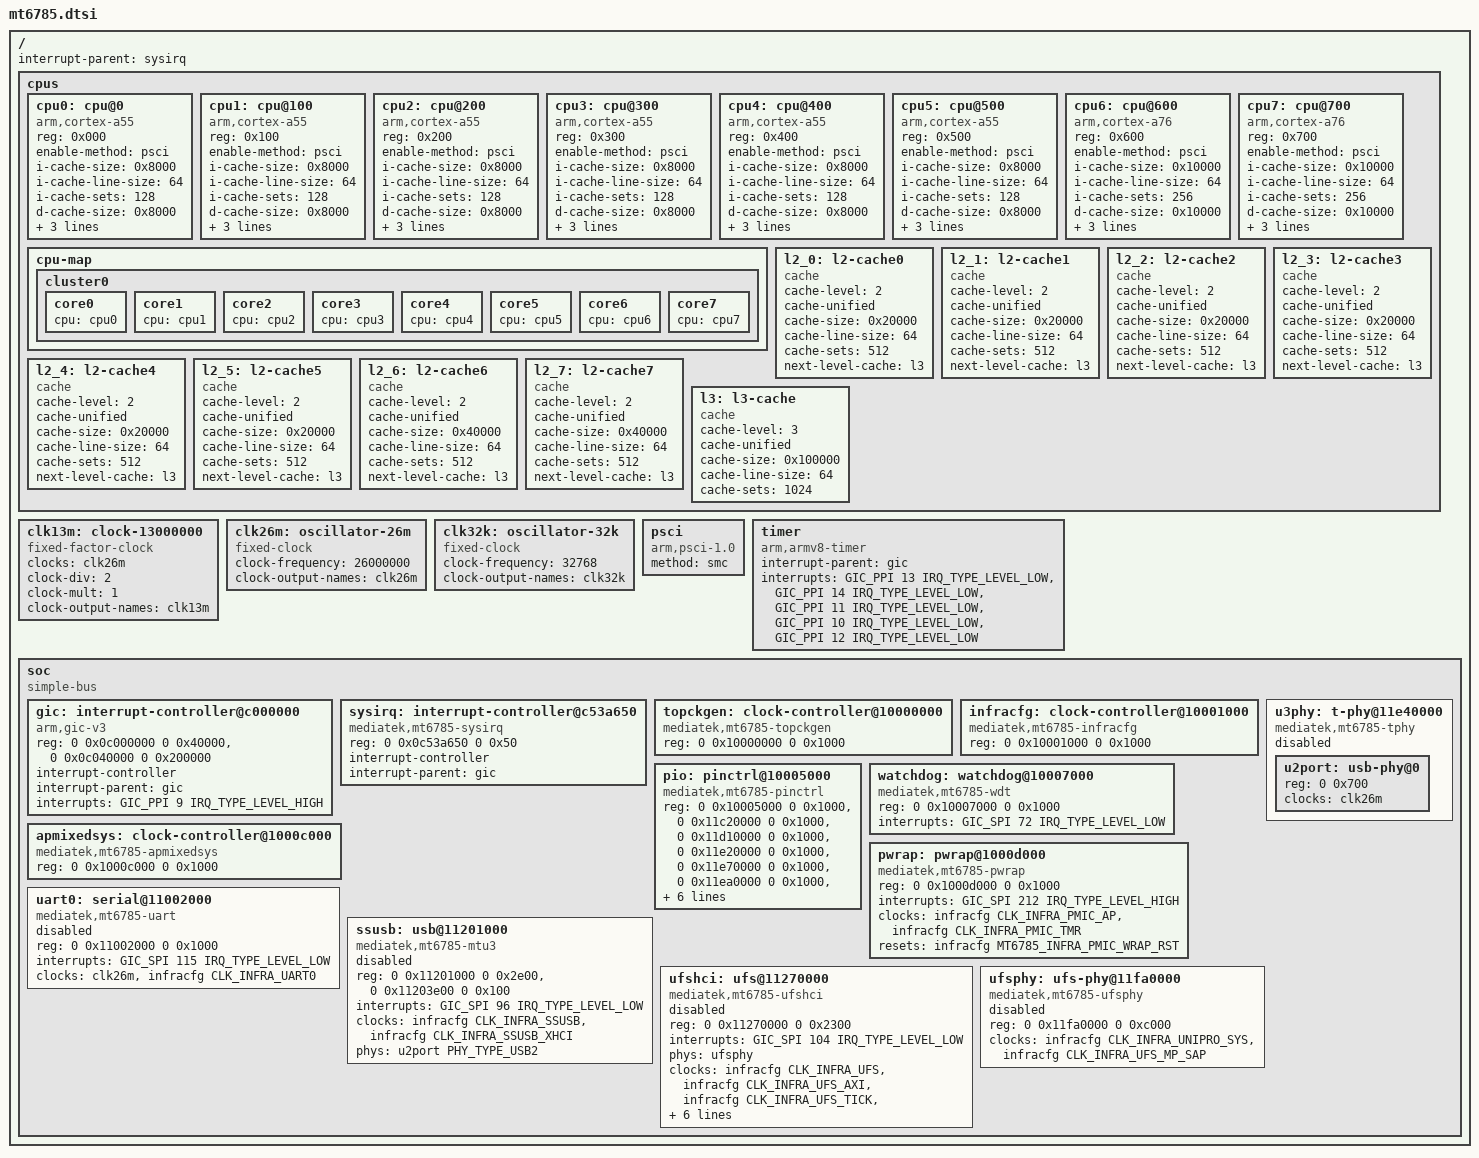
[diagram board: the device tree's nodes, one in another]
// SPDX-License-Identifier: (GPL-2.0 OR MIT)
/* Copyright (c) 2025 Dinolek <git@dinolek.me> */

#include <dt-bindings/clock/mediatek,mt6785-clk.h>
#include <dt-bindings/interrupt-controller/arm-gic.h>
#include <dt-bindings/interrupt-controller/irq.h>
#include <dt-bindings/phy/phy.h>
#include <dt-bindings/reset/mediatek,mt6785-resets.h>

/ {
	#address-cells = <2>;
	#size-cells = <2>;
	interrupt-parent = <&sysirq>;

	cpus {
		#address-cells = <1>;
		#size-cells = <0>;

		cpu0: cpu@0 {
			device_type = "cpu";
			compatible = "arm,cortex-a55";
			reg = <0x000>;
			enable-method = "psci";
			i-cache-size = <0x8000>;
			i-cache-line-size = <64>;
			i-cache-sets = <128>;
			d-cache-size = <0x8000>;
			d-cache-line-size = <64>;
			d-cache-sets = <128>;
			next-level-cache = <&l2_0>;
		};

		cpu1: cpu@100 {
			device_type = "cpu";
			compatible = "arm,cortex-a55";
			reg = <0x100>;
			enable-method = "psci";
			i-cache-size = <0x8000>;
			i-cache-line-size = <64>;
			i-cache-sets = <128>;
			d-cache-size = <0x8000>;
			d-cache-line-size = <64>;
			d-cache-sets = <128>;
			next-level-cache = <&l2_1>;
		};

		cpu2: cpu@200 {
			device_type = "cpu";
			compatible = "arm,cortex-a55";
			reg = <0x200>;
			enable-method = "psci";
			i-cache-size = <0x8000>;
			i-cache-line-size = <64>;
			i-cache-sets = <128>;
			d-cache-size = <0x8000>;
			d-cache-line-size = <64>;
			d-cache-sets = <128>;
			next-level-cache = <&l2_2>;
		};

		cpu3: cpu@300 {
			device_type = "cpu";
			compatible = "arm,cortex-a55";
			reg = <0x300>;
			enable-method = "psci";
			i-cache-size = <0x8000>;
			i-cache-line-size = <64>;
			i-cache-sets = <128>;
			d-cache-size = <0x8000>;
			d-cache-line-size = <64>;
			d-cache-sets = <128>;
			next-level-cache = <&l2_3>;
		};

		cpu4: cpu@400 {
			device_type = "cpu";
			compatible = "arm,cortex-a55";
			reg = <0x400>;
			enable-method = "psci";
			i-cache-size = <0x8000>;
			i-cache-line-size = <64>;
			i-cache-sets = <128>;
			d-cache-size = <0x8000>;
			d-cache-line-size = <64>;
			d-cache-sets = <128>;
			next-level-cache = <&l2_4>;
		};

		cpu5: cpu@500 {
			device_type = "cpu";
			compatible = "arm,cortex-a55";
			reg = <0x500>;
			enable-method = "psci";
			i-cache-size = <0x8000>;
			i-cache-line-size = <64>;
			i-cache-sets = <128>;
			d-cache-size = <0x8000>;
			d-cache-line-size = <64>;
			d-cache-sets = <128>;
			next-level-cache = <&l2_5>;
		};

		cpu6: cpu@600 {
			device_type = "cpu";
			compatible = "arm,cortex-a76";
			reg = <0x600>;
			enable-method = "psci";
			i-cache-size = <0x10000>;
			i-cache-line-size = <64>;
			i-cache-sets = <256>;
			d-cache-size = <0x10000>;
			d-cache-line-size = <64>;
			d-cache-sets = <256>;
			next-level-cache = <&l2_6>;
		};

		cpu7: cpu@700 {
			device_type = "cpu";
			compatible = "arm,cortex-a76";
			reg = <0x700>;
			enable-method = "psci";
			i-cache-size = <0x10000>;
			i-cache-line-size = <64>;
			i-cache-sets = <256>;
			d-cache-size = <0x10000>;
			d-cache-line-size = <64>;
			d-cache-sets = <256>;
			next-level-cache = <&l2_7>;
		};
		cpu-map {
			cluster0 {
				core0 {
					cpu = <&cpu0>;
				};
				core1 {
					cpu = <&cpu1>;
				};
				core2 {
					cpu = <&cpu2>;
				};
				core3 {
					cpu = <&cpu3>;
				};
				core4 {
					cpu = <&cpu4>;
				};
				core5 {
					cpu = <&cpu5>;
				};
				core6 {
					cpu = <&cpu6>;
				};
				core7 {
					cpu = <&cpu7>;
				};
			};
		};

		l2_0: l2-cache0 {
			compatible = "cache";
			cache-level = <2>;
			cache-unified;
			cache-size = <0x20000>;
			cache-line-size = <64>;
			cache-sets = <512>;
			next-level-cache = <&l3>;
		};

		l2_1: l2-cache1 {
			compatible = "cache";
			cache-level = <2>;
			cache-unified;
			cache-size = <0x20000>;
			cache-line-size = <64>;
			cache-sets = <512>;
			next-level-cache = <&l3>;
		};

		l2_2: l2-cache2 {
			compatible = "cache";
			cache-level = <2>;
			cache-unified;
			cache-size = <0x20000>;
			cache-line-size = <64>;
			cache-sets = <512>;
			next-level-cache = <&l3>;
		};

		l2_3: l2-cache3 {
			compatible = "cache";
			cache-level = <2>;
			cache-unified;
			cache-size = <0x20000>;
			cache-line-size = <64>;
			cache-sets = <512>;
			next-level-cache = <&l3>;
		};

		l2_4: l2-cache4 {
			compatible = "cache";
			cache-level = <2>;
			cache-unified;
			cache-size = <0x20000>;
			cache-line-size = <64>;
			cache-sets = <512>;
			next-level-cache = <&l3>;
		};

		l2_5: l2-cache5 {
			compatible = "cache";
			cache-level = <2>;
			cache-unified;
			cache-size = <0x20000>;
			cache-line-size = <64>;
			cache-sets = <512>;
			next-level-cache = <&l3>;
		};

		l2_6: l2-cache6 {
			compatible = "cache";
			cache-level = <2>;
			cache-unified;
			cache-size = <0x40000>;
			cache-line-size = <64>;
			cache-sets = <512>;
			next-level-cache = <&l3>;
		};

		l2_7: l2-cache7 {
			compatible = "cache";
			cache-level = <2>;
			cache-unified;
			cache-size = <0x40000>;
			cache-line-size = <64>;
			cache-sets = <512>;
			next-level-cache = <&l3>;
		};

		l3: l3-cache {
			compatible = "cache";
			cache-level = <3>;
			cache-unified;
			cache-size = <0x100000>;
			cache-line-size = <64>;
			cache-sets = <1024>;
		};
	};

	clk13m: clock-13000000 {
		compatible = "fixed-factor-clock";
		#clock-cells = <0>;
		clocks = <&clk26m>;
		clock-div = <2>;
		clock-mult = <1>;
		clock-output-names = "clk13m";
	};

	clk26m: oscillator-26m {
		compatible = "fixed-clock";
		#clock-cells = <0>;
		clock-frequency = <26000000>;
		clock-output-names = "clk26m";
	};

	clk32k: oscillator-32k {
		compatible = "fixed-clock";
		#clock-cells = <0>;
		clock-frequency = <32768>;
		clock-output-names = "clk32k";
	};

	psci {
		compatible = "arm,psci-1.0";
		method = "smc";
	};

	timer {
		compatible = "arm,armv8-timer";
		interrupt-parent = <&gic>;
		interrupts = <GIC_PPI 13 IRQ_TYPE_LEVEL_LOW>,
			     <GIC_PPI 14 IRQ_TYPE_LEVEL_LOW>,
			     <GIC_PPI 11 IRQ_TYPE_LEVEL_LOW>,
			     <GIC_PPI 10 IRQ_TYPE_LEVEL_LOW>,
			     <GIC_PPI 12 IRQ_TYPE_LEVEL_LOW>;
	};

	soc {
		compatible = "simple-bus";
		#address-cells = <2>;
		#size-cells = <2>;
		ranges;

		gic: interrupt-controller@c000000 {
			compatible = "arm,gic-v3";
			reg = <0 0x0c000000 0 0x40000>,
			      <0 0x0c040000 0 0x200000>;
			#interrupt-cells = <3>;
			#address-cells = <0>;
			interrupt-controller;
			interrupt-parent = <&gic>;
			interrupts = <GIC_PPI 9 IRQ_TYPE_LEVEL_HIGH>;
		};

		sysirq: interrupt-controller@c53a650 {
			compatible = "mediatek,mt6785-sysirq", "mediatek,mt6577-sysirq";
			reg = <0 0x0c53a650 0 0x50>;
			#interrupt-cells = <3>;
			#address-cells = <0>;
			interrupt-controller;
			interrupt-parent = <&gic>;
		};

		topckgen: clock-controller@10000000 {
			compatible = "mediatek,mt6785-topckgen", "syscon";
			reg = <0 0x10000000 0 0x1000>;
			#clock-cells = <1>;
		};

		infracfg: clock-controller@10001000 {
			compatible = "mediatek,mt6785-infracfg", "syscon";
			reg = <0 0x10001000 0 0x1000>;
			#clock-cells = <1>;
			#reset-cells = <1>;
		};

		pio: pinctrl@10005000 {
			compatible = "mediatek,mt6785-pinctrl";
			reg = <0 0x10005000 0 0x1000>,
			      <0 0x11c20000 0 0x1000>,
			      <0 0x11d10000 0 0x1000>,
			      <0 0x11e20000 0 0x1000>,
			      <0 0x11e70000 0 0x1000>,
			      <0 0x11ea0000 0 0x1000>,
			      <0 0x11f20000 0 0x1000>,
			      <0 0x11f30000 0 0x1000>,
			      <0 0x1000b000 0 0x1000>;
			reg-names = "base", "rm", "br", "bl", "lb", "rt", "lt", "tl", "eint";
			interrupts = <GIC_SPI 204 IRQ_TYPE_LEVEL_HIGH>;
			gpio-controller;
			#gpio-cells = <2>;
			gpio-ranges = <&pio 0 0 203>;
			interrupt-controller;
			#interrupt-cells = <2>;
		};

		watchdog: watchdog@10007000 {
			compatible = "mediatek,mt6785-wdt";
			reg = <0 0x10007000 0 0x1000>;
			interrupts = <GIC_SPI 72 IRQ_TYPE_LEVEL_LOW>;
			#reset-cells = <1>;
		};

		apmixedsys: clock-controller@1000c000 {
			compatible = "mediatek,mt6785-apmixedsys", "syscon";
			reg = <0 0x1000c000 0 0x1000>;
			#clock-cells = <1>;
		};

		pwrap: pwrap@1000d000 {
			compatible = "mediatek,mt6785-pwrap";
			reg = <0 0x1000d000 0 0x1000>;
			reg-names = "pwrap";
			interrupts = <GIC_SPI 212 IRQ_TYPE_LEVEL_HIGH>;
			clocks = <&infracfg CLK_INFRA_PMIC_AP>,
				 <&infracfg CLK_INFRA_PMIC_TMR>;
			clock-names = "spi", "wrap";
			resets = <&infracfg MT6785_INFRA_PMIC_WRAP_RST>;
			reset-names = "pwrap";
		};

		uart0: serial@11002000 {
			compatible = "mediatek,mt6785-uart", "mediatek,mt6577-uart";
			reg = <0 0x11002000 0 0x1000>;
			interrupts = <GIC_SPI 115 IRQ_TYPE_LEVEL_LOW>;
			clocks = <&clk26m>, <&infracfg CLK_INFRA_UART0>;
			clock-names = "baud", "bus";
			status = "disabled";
		};

		ssusb: usb@11201000 {
			compatible = "mediatek,mt6785-mtu3", "mediatek,mtu3";
			reg = <0 0x11201000 0 0x2e00>,
			      <0 0x11203e00 0 0x100>;
			reg-names = "mac", "ippc";
			interrupts = <GIC_SPI 96 IRQ_TYPE_LEVEL_LOW>;
			clocks = <&infracfg CLK_INFRA_SSUSB>,
				 <&infracfg CLK_INFRA_SSUSB_XHCI>;
			clock-names = "sys_ck", "ref_ck";
			phys = <&u2port PHY_TYPE_USB2>;
			status = "disabled";
		};

		ufshci: ufs@11270000 {
			compatible = "mediatek,mt6785-ufshci";
			reg = <0 0x11270000 0 0x2300>;
			interrupts = <GIC_SPI 104 IRQ_TYPE_LEVEL_LOW>;
			phys = <&ufsphy>;
			clocks = <&infracfg CLK_INFRA_UFS>,
				 <&infracfg CLK_INFRA_UFS_AXI>,
				 <&infracfg CLK_INFRA_UFS_TICK>,
				 <&infracfg CLK_INFRA_UNIPRO_MBIST>,
				 <&infracfg CLK_INFRA_UNIPRO_TICK>;
			clock-names = "ufs", "ufs-axi", "ufs-tick", "unipro-mbist",
				      "unipro-tick";
			freq-table-hz = <0 0>, <0 0>, <0 0>, <0 0>, <0 0>;
			resets = <&infracfg MT6785_INFRA_UFS_HCI_RST>,
				 <&infracfg MT6785_INFRA_UFS_UNIPRO_RST>,
				 <&infracfg MT6785_INFRA_UFS_AES_RST>;
			reset-names = "hci_rst", "unipro_rst", "crypto_rst";
			status = "disabled";
		};

		u3phy: t-phy@11e40000 {
			compatible = "mediatek,mt6785-tphy", "mediatek,generic-tphy-v2";
			#address-cells = <1>;
			#size-cells = <1>;
			ranges = <0 0 0x11e40000 0x1000>;
			status = "disabled";

			u2port: usb-phy@0 {
				reg = <0 0x700>;
				clocks = <&clk26m>;
				clock-names = "ref";
				#phy-cells = <1>;
			};
		};

		ufsphy: ufs-phy@11fa0000 {
			compatible = "mediatek,mt6785-ufsphy", "mediatek,mt8183-ufsphy";
			reg = <0 0x11fa0000 0 0xc000>;
			clocks = <&infracfg CLK_INFRA_UNIPRO_SYS>,
				 <&infracfg CLK_INFRA_UFS_MP_SAP>;
			clock-names = "unipro", "mp";
			#phy-cells = <0>;
			status = "disabled";
		};
	};
};
